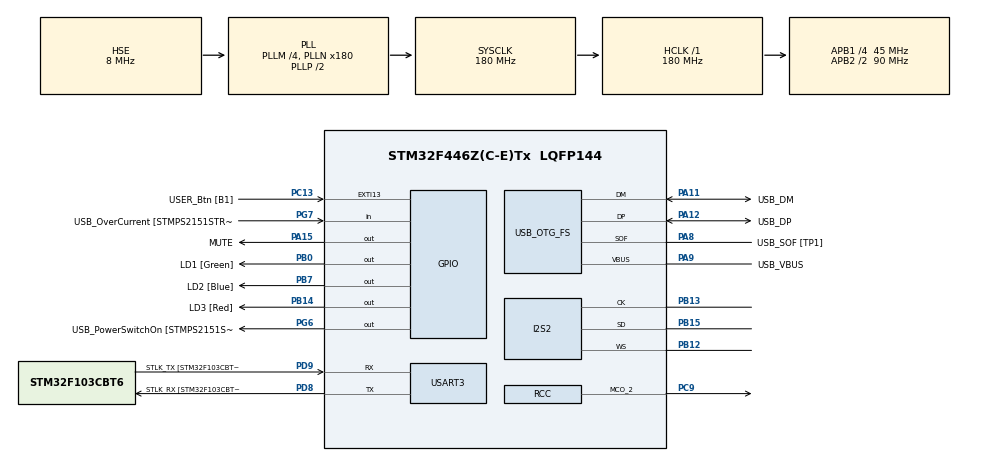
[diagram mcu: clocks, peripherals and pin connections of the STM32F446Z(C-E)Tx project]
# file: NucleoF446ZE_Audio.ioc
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Dma.Request0=SPI2_TX
Dma.SPI2_TX.0.Direction=DMA_MEMORY_TO_PERIPH
Dma.SPI2_TX.0.FIFOMode=DMA_FIFOMODE_ENABLE
Dma.SPI2_TX.0.FIFOThreshold=DMA_FIFO_THRESHOLD_FULL
Dma.SPI2_TX.0.Instance=DMA1_Stream4
Dma.SPI2_TX.0.MemBurst=DMA_MBURST_SINGLE
Dma.SPI2_TX.0.MemDataAlignment=DMA_MDATAALIGN_HALFWORD
Dma.SPI2_TX.0.MemInc=DMA_MINC_ENABLE
Dma.SPI2_TX.0.Mode=DMA_CIRCULAR
Dma.SPI2_TX.0.PeriphBurst=DMA_PBURST_SINGLE
Dma.SPI2_TX.0.PeriphDataAlignment=DMA_PDATAALIGN_HALFWORD
Dma.SPI2_TX.0.PeriphInc=DMA_PINC_DISABLE
Dma.SPI2_TX.0.Priority=DMA_PRIORITY_HIGH
I2S2.AudioFreq=I2S_AUDIOFREQ_96K
I2S2.DataFormat=I2S_DATAFORMAT_24B
I2S2.ErrorAudioFreq=-0.01 %
I2S2.FullDuplexMode=I2S_FULLDUPLEXMODE_DISABLE
I2S2.Instance=SPI$Index
I2S2.RealAudioFreq=95.982 KHz
I2S2.VirtualMode=I2S_MODE_MASTER
Mcu.Family=STM32F4
Mcu.Name=STM32F446Z(C-E)Tx
Mcu.Package=LQFP144
NVIC.DMA1_Stream4_IRQn=true\:5\:0\:true\:false\:true\:false\:true\:true
NVIC.OTG_FS_IRQn=true\:5\:0\:true\:false\:true\:false\:true\:true
NVIC.PriorityGroup=NVIC_PRIORITYGROUP_4
NVIC.USART3_IRQn=true\:0\:0\:false\:false\:true\:true\:true\:true
PA10.GPIO_Label=USB_ID
PA10.Signal=USB_OTG_FS_ID
PA11.GPIO_Label=USB_DM
PA11.Mode=Device_Only
PA11.Signal=USB_OTG_FS_DM
PA12.GPIO_Label=USB_DP
PA12.Mode=Device_Only
PA12.Signal=USB_OTG_FS_DP
PA13.GPIO_Label=TMS
PA13.Mode=Serial_Wire
PA13.Signal=SYS_JTMS-SWDIO
PA14.GPIO_Label=TCK
PA14.Mode=Serial_Wire
PA14.Signal=SYS_JTCK-SWCLK
PA15.GPIO_Label=MUTE
PA15.Signal=GPIO_Output
PA8.GPIO_Label=USB_SOF [TP1]
PA8.Mode=Activate_SOF_FS
PA8.Signal=USB_OTG_FS_SOF
PA9.GPIO_Label=USB_VBUS
PA9.Mode=Activate_VBUS
PA9.Signal=USB_OTG_FS_VBUS
PB0.GPIO_Label=LD1 [Green]
PB0.Signal=GPIO_Output
PB12.Mode=Half_Duplex_Master
PB12.Signal=I2S2_WS
PB13.Mode=Half_Duplex_Master
PB13.Signal=I2S2_CK
PB14.GPIO_Label=LD3 [Red]
PB14.Signal=GPIO_Output
PB15.Mode=Half_Duplex_Master
PB15.Signal=I2S2_SD
PB7.GPIO_Label=LD2 [Blue]
PB7.Signal=GPIO_Output
PC13.GPIO_Label=USER_Btn [B1]
PC13.Signal=GPXTI13
PC14-OSC32_IN.Mode=LSE-External-Oscillator
PC14-OSC32_IN.Signal=RCC_OSC32_IN
PC15-OSC32_OUT.Mode=LSE-External-Oscillator
PC15-OSC32_OUT.Signal=RCC_OSC32_OUT
PC6.Signal=I2S2_MCK
PC9.Mode=Clock-out-2
PC9.Signal=RCC_MCO_2
PD8.GPIO_Label=STLK_RX [STM32F103CBT6_PA3]
PD8.Mode=Asynchronous
PD8.Signal=USART3_TX
PD9.GPIO_Label=STLK_TX [STM32F103CBT6_PA2]
PD9.Mode=Asynchronous
PD9.Signal=USART3_RX
PG6.GPIO_Label=USB_PowerSwitchOn [STMPS2151STR_EN]
PG6.Signal=GPIO_Output
PG7.GPIO_Label=USB_OverCurrent [STMPS2151STR_FAULT]
PG7.Signal=GPIO_Input
PH0-OSC_IN.GPIO_Label=MCO [STM32F103CBT6_PA8]
PH0-OSC_IN.Mode=HSE-External-Clock-Source
PH0-OSC_IN.Signal=RCC_OSC_IN
PH1-OSC_OUT.Mode=HSE-External-Clock-Source
PH1-OSC_OUT.Signal=RCC_OSC_OUT
ProjectManager.HeapSize=0x200
ProjectManager.StackSize=0x400
ProjectManager.TargetToolchain=STM32CubeIDE
RCC.48MHZClocksFreq_Value=24000000
RCC.AHBFreq_Value=180000000
RCC.APB1CLKDivider=RCC_HCLK_DIV4
RCC.APB1Freq_Value=45000000
RCC.APB1TimFreq_Value=90000000
RCC.APB2CLKDivider=RCC_HCLK_DIV2
RCC.APB2Freq_Value=90000000
RCC.APB2TimFreq_Value=180000000
RCC.CortexFreq_Value=180000000
RCC.EXTERNAL_CLOCK_VALUE=24576000
RCC.HCLKFreq_Value=180000000
RCC.HSE_VALUE=8000000
RCC.HSI_VALUE=16000000
RCC.PLLI2SM=7
RCC.PLLI2SN=129
RCC.PLLI2SR=6
RCC.PLLM=4
RCC.PLLMUL=RCC_PLL_MUL9
RCC.PLLN=180
RCC.PLLQ=8
RCC.PLLSAIM=8
RCC.PLLSAIP=RCC_PLLSAIP_DIV4
RCC.PRESCALERUSB=RCC_USBCLKSOURCE_PLL_DIV1_5
RCC.RCC_MCO2Source=RCC_MCO2SOURCE_PLLI2SCLK
RCC.SYSCLKFreq_VALUE=180000000
RCC.SYSCLKSource=RCC_SYSCLKSOURCE_PLLCLK
RCC.SYSCLKSourceVirtual=RCC_SYSCLKSOURCE_PLLCLK
RCC.USBCLockSelection=RCC_CLK48CLKSOURCE_PLLSAIP
RCC.USBFreq_Value=48000000
RCC.VCOOutputFreq_Value=360000000
USART3.VirtualMode=VM_ASYNC
USB_DEVICE.CLASS_NAME_FS=AUDIO
USB_DEVICE.USBD_AUDIO_FREQ-AUDIO_FS=48000
USB_DEVICE.USBD_DEBUG_LEVEL-AUDIO_FS=3
USB_DEVICE.VirtualMode-AUDIO_FS=Audio
USB_DEVICE.VirtualModeFS=Audio_FS
USB_OTG_FS.VirtualMode=Device_Only
VP_CRC_VS_CRC.Mode=CRC_Activate
VP_USB_DEVICE_VS_USB_DEVICE_AUDIO_FS.Mode=AUDIO_FS
board=NUCLEO-F446ZE

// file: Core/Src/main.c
/* USER CODE BEGIN Header */
/**
  ******************************************************************************
  * @file           : main.c
  * @brief          : Main program body
  ******************************************************************************
  * @attention
  *
  * Copyright (c) 2024 STMicroelectronics.
  * All rights reserved.
  *
  * This software is licensed under terms that can be found in the LICENSE file
  * in the root directory of this software component.
  * If no LICENSE file comes with this software, it is provided AS-IS.
  *
  ******************************************************************************
  */
/* USER CODE END Header */
#include "main.h"
#include "usb_device.h"

/* USER CODE BEGIN Includes */

#include "retarget.h"

/* USER CODE END Includes */

CRC_HandleTypeDef hcrc;

I2S_HandleTypeDef hi2s2;
DMA_HandleTypeDef hdma_spi2_tx;

UART_HandleTypeDef huart3;

void SystemClock_Config(void);
void PeriphCommonClock_Config(void);
static void MX_GPIO_Init(void);
static void MX_DMA_Init(void);
static void MX_USART3_UART_Init(void);
static void MX_CRC_Init(void);
static void MX_I2S2_Init(void);

int main(void)
{

  /* MCU Configuration--------------------------------------------------------*/

  /* Reset of all peripherals, Initializes the Flash interface and the Systick. */
  HAL_Init();

  /* Configure the system clock */
  SystemClock_Config();

/* Configure the peripherals common clocks */
  PeriphCommonClock_Config();

  /* Initialize all configured peripherals */
  MX_GPIO_Init();
  MX_DMA_Init();
  MX_USART3_UART_Init();
  MX_CRC_Init();
  MX_I2S2_Init();
  MX_USB_DEVICE_Init();
  /* USER CODE BEGIN 2 */

  RetargetInit(&huart3);
  printf("init done\n");

  /* USER CODE END 2 */

  /* Infinite loop */
  while (1)
  {

  }
}

void SystemClock_Config(void)
{
  RCC_OscInitTypeDef RCC_OscInitStruct = {0};
  RCC_ClkInitTypeDef RCC_ClkInitStruct = {0};

  /** Configure the main internal regulator output voltage
  */
  __HAL_RCC_PWR_CLK_ENABLE();
  __HAL_PWR_VOLTAGESCALING_CONFIG(PWR_REGULATOR_VOLTAGE_SCALE1);

  /** Initializes the RCC Oscillators according to the specified parameters
  * in the RCC_OscInitTypeDef structure.
  */
  RCC_OscInitStruct.OscillatorType = RCC_OSCILLATORTYPE_HSE;
  RCC_OscInitStruct.HSEState = RCC_HSE_BYPASS;
  RCC_OscInitStruct.HSIState = RCC_HSI_ON;
  RCC_OscInitStruct.HSICalibrationValue = RCC_HSICALIBRATION_DEFAULT;
  RCC_OscInitStruct.PLL.PLLState = RCC_PLL_ON;
  RCC_OscInitStruct.PLL.PLLSource = RCC_PLLSOURCE_HSE;
  RCC_OscInitStruct.PLL.PLLM = 4;
  RCC_OscInitStruct.PLL.PLLN = 180;
  RCC_OscInitStruct.PLL.PLLP = RCC_PLLP_DIV2;
  RCC_OscInitStruct.PLL.PLLQ = 8;
  RCC_OscInitStruct.PLL.PLLR = 2;
  if (HAL_RCC_OscConfig(&RCC_OscInitStruct) != HAL_OK)
  {
    Error_Handler();
  }

  /** Activate the Over-Drive mode
  */
  if (HAL_PWREx_EnableOverDrive() != HAL_OK)
  {
    Error_Handler();
  }

  /** Initializes the CPU, AHB and APB buses clocks
  */
  RCC_ClkInitStruct.ClockType = RCC_CLOCKTYPE_HCLK|RCC_CLOCKTYPE_SYSCLK
                              |RCC_CLOCKTYPE_PCLK1|RCC_CLOCKTYPE_PCLK2;
  RCC_ClkInitStruct.SYSCLKSource = RCC_SYSCLKSOURCE_PLLCLK;
  RCC_ClkInitStruct.AHBCLKDivider = RCC_SYSCLK_DIV1;
  RCC_ClkInitStruct.APB1CLKDivider = RCC_HCLK_DIV4;
  RCC_ClkInitStruct.APB2CLKDivider = RCC_HCLK_DIV2;

  if (HAL_RCC_ClockConfig(&RCC_ClkInitStruct, FLASH_LATENCY_5) != HAL_OK)
  {
    Error_Handler();
  }
  HAL_RCC_MCOConfig(RCC_MCO2, RCC_MCO2SOURCE_PLLI2SCLK, RCC_MCODIV_1);
}

void PeriphCommonClock_Config(void)
{
  RCC_PeriphCLKInitTypeDef PeriphClkInitStruct = {0};

  /** Initializes the peripherals clock
  */
  PeriphClkInitStruct.PeriphClockSelection = RCC_PERIPHCLK_PLLI2S|RCC_PERIPHCLK_I2S_APB1;
  PeriphClkInitStruct.PLLI2S.PLLI2SN = 129;
  PeriphClkInitStruct.PLLI2S.PLLI2SP = RCC_PLLI2SP_DIV2;
  PeriphClkInitStruct.PLLI2S.PLLI2SM = 7;
  PeriphClkInitStruct.PLLI2S.PLLI2SR = 6;
  PeriphClkInitStruct.PLLI2S.PLLI2SQ = 2;
  PeriphClkInitStruct.PLLI2SDivQ = 1;
  PeriphClkInitStruct.I2sApb1ClockSelection = RCC_I2SAPB1CLKSOURCE_PLLI2S;
  if (HAL_RCCEx_PeriphCLKConfig(&PeriphClkInitStruct) != HAL_OK)
  {
    Error_Handler();
  }
}

static void MX_CRC_Init(void)
{

  hcrc.Instance = CRC;
  if (HAL_CRC_Init(&hcrc) != HAL_OK)
  {
    Error_Handler();
  }

}

static void MX_I2S2_Init(void)
{

  hi2s2.Instance = SPI2;
  hi2s2.Init.Mode = I2S_MODE_MASTER_TX;
  hi2s2.Init.Standard = I2S_STANDARD_PHILIPS;
  hi2s2.Init.DataFormat = I2S_DATAFORMAT_24B;
  hi2s2.Init.MCLKOutput = I2S_MCLKOUTPUT_DISABLE;
  hi2s2.Init.AudioFreq = I2S_AUDIOFREQ_96K;
  hi2s2.Init.CPOL = I2S_CPOL_LOW;
  hi2s2.Init.ClockSource = I2S_CLOCK_PLL;
  hi2s2.Init.FullDuplexMode = I2S_FULLDUPLEXMODE_DISABLE;
  if (HAL_I2S_Init(&hi2s2) != HAL_OK)
  {
    Error_Handler();
  }

}

static void MX_USART3_UART_Init(void)
{

  huart3.Instance = USART3;
  huart3.Init.BaudRate = 115200;
  huart3.Init.WordLength = UART_WORDLENGTH_8B;
  huart3.Init.StopBits = UART_STOPBITS_1;
  huart3.Init.Parity = UART_PARITY_NONE;
  huart3.Init.Mode = UART_MODE_TX_RX;
  huart3.Init.HwFlowCtl = UART_HWCONTROL_NONE;
  huart3.Init.OverSampling = UART_OVERSAMPLING_16;
  if (HAL_UART_Init(&huart3) != HAL_OK)
  {
    Error_Handler();
  }

}

static void MX_DMA_Init(void)
{

  /* DMA controller clock enable */
  __HAL_RCC_DMA1_CLK_ENABLE();

  /* DMA interrupt init */
  /* DMA1_Stream4_IRQn interrupt configuration */
  HAL_NVIC_SetPriority(DMA1_Stream4_IRQn, 5, 0);
  HAL_NVIC_EnableIRQ(DMA1_Stream4_IRQn);

}

static void MX_GPIO_Init(void)
{
  GPIO_InitTypeDef GPIO_InitStruct = {0};

  /* GPIO Ports Clock Enable */
  __HAL_RCC_GPIOC_CLK_ENABLE();
  __HAL_RCC_GPIOH_CLK_ENABLE();
  __HAL_RCC_GPIOB_CLK_ENABLE();
  __HAL_RCC_GPIOD_CLK_ENABLE();
  __HAL_RCC_GPIOG_CLK_ENABLE();
  __HAL_RCC_GPIOA_CLK_ENABLE();

  /*Configure GPIO pin Output Level */
  HAL_GPIO_WritePin(GPIOB, LD1_Pin|LD3_Pin|LD2_Pin, GPIO_PIN_RESET);

  /*Configure GPIO pin Output Level */
  HAL_GPIO_WritePin(USB_PowerSwitchOn_GPIO_Port, USB_PowerSwitchOn_Pin, GPIO_PIN_RESET);

  /*Configure GPIO pin Output Level */
  HAL_GPIO_WritePin(MUTE_GPIO_Port, MUTE_Pin, GPIO_PIN_RESET);

  /*Configure GPIO pin : USER_Btn_Pin */
  GPIO_InitStruct.Pin = USER_Btn_Pin;
  GPIO_InitStruct.Mode = GPIO_MODE_IT_RISING;
  GPIO_InitStruct.Pull = GPIO_NOPULL;
  HAL_GPIO_Init(USER_Btn_GPIO_Port, &GPIO_InitStruct);

  /*Configure GPIO pins : LD1_Pin LD3_Pin LD2_Pin */
  GPIO_InitStruct.Pin = LD1_Pin|LD3_Pin|LD2_Pin;
  GPIO_InitStruct.Mode = GPIO_MODE_OUTPUT_PP;
  GPIO_InitStruct.Pull = GPIO_NOPULL;
  GPIO_InitStruct.Speed = GPIO_SPEED_FREQ_LOW;
  HAL_GPIO_Init(GPIOB, &GPIO_InitStruct);

  /*Configure GPIO pin : USB_PowerSwitchOn_Pin */
  GPIO_InitStruct.Pin = USB_PowerSwitchOn_Pin;
  GPIO_InitStruct.Mode = GPIO_MODE_OUTPUT_PP;
  GPIO_InitStruct.Pull = GPIO_NOPULL;
  GPIO_InitStruct.Speed = GPIO_SPEED_FREQ_LOW;
  HAL_GPIO_Init(USB_PowerSwitchOn_GPIO_Port, &GPIO_InitStruct);

  /*Configure GPIO pin : USB_OverCurrent_Pin */
  GPIO_InitStruct.Pin = USB_OverCurrent_Pin;
  GPIO_InitStruct.Mode = GPIO_MODE_INPUT;
  GPIO_InitStruct.Pull = GPIO_NOPULL;
  HAL_GPIO_Init(USB_OverCurrent_GPIO_Port, &GPIO_InitStruct);

  /*Configure GPIO pin : PC9 */
  GPIO_InitStruct.Pin = GPIO_PIN_9;
  GPIO_InitStruct.Mode = GPIO_MODE_AF_PP;
  GPIO_InitStruct.Pull = GPIO_NOPULL;
  GPIO_InitStruct.Speed = GPIO_SPEED_FREQ_LOW;
  GPIO_InitStruct.Alternate = GPIO_AF0_MCO;
  HAL_GPIO_Init(GPIOC, &GPIO_InitStruct);

  /*Configure GPIO pin : MUTE_Pin */
  GPIO_InitStruct.Pin = MUTE_Pin;
  GPIO_InitStruct.Mode = GPIO_MODE_OUTPUT_PP;
  GPIO_InitStruct.Pull = GPIO_NOPULL;
  GPIO_InitStruct.Speed = GPIO_SPEED_FREQ_LOW;
  HAL_GPIO_Init(MUTE_GPIO_Port, &GPIO_InitStruct);

}

void Error_Handler(void)
{
  __disable_irq();
  while (1)
  {
  }
}
